# TOP_PBIST_TOP_PBIST register map
Vendor: Texas Instruments
Peripheral module from a debugger description file (folder AM263).
Registers are 32-bit, read-write, reset 0x0 unless marked. A register's access mark holds for its fields unless they carry their own. Offsets are as the file gives them; lines under a group give offsets from that group; [hi:lo] are bit positions; {n}, {i} and the like mark numbered series; 'fields as' and 'values as' point back to an identical list; <NAME> marks a mode.

## TOP_PBIST_TOP_PBIST
0x100 TOP_PBIST_PBIST_A0 16-bit
  [15:0] PBIST_CI2 — TI Internal Register.Reserved for HW RnD
0x104 TOP_PBIST_PBIST_A1 16-bit
  [15:0] PBIST_CI3 — TI Internal Register.Reserved for HW RnD
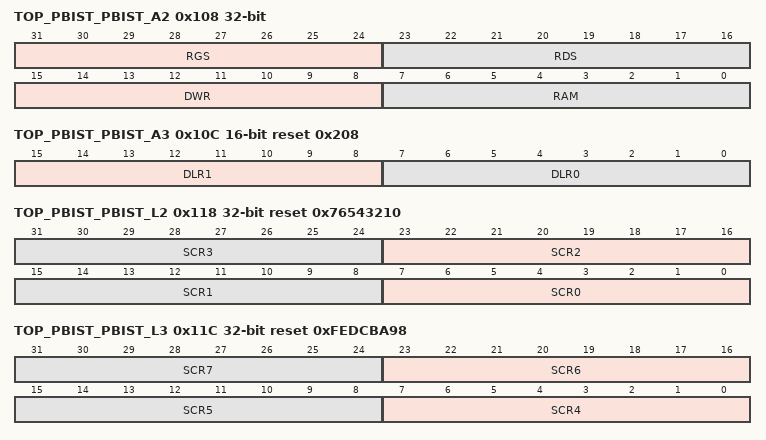
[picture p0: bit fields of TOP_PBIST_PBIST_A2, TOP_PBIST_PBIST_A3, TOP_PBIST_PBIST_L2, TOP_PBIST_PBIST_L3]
0x108 TOP_PBIST_PBIST_A2
  [31:24] RGS — TI Internal Register.Reserved for HW RnD These registers do not have a default value after reset.
  [23:16] RDS — TI Internal Register.Reserved for HW RnD These registers do not have a default value after reset.
  [15:8] DWR — TI Internal Register.Reserved for HW RnD These registers do not have a default value after reset.
  [7:0] RAM — TI Internal Register.Reserved for HW RnD These registers do not have a default value after reset.
0x10C TOP_PBIST_PBIST_A3 16-bit reset 0x208
  [15:8] DLR1 — Datalogger Register[8] : Reserevd[9] : Default Testing Mode. When in this mode, ROM-based testing is kicked off. If the intention is to perform go/no-go testing via config, write to both this bit and bit [2] ofthe Datalogger Register simultaneously[15:10] : Reserevd
  [7:0] DLR0 — Datalogger Register[1:0] : Reserved[2] : ROM-based testing mode. Setting this bit to 1 enables the PBIST controller to execute test algorithms that arestored in the PBIST ROM[3] : Do not change this bit from its default value of 1[4] : Config access mode. Setting this bit allows the host processor to configure the PBIST controller registers[7:5] : Reserved
0x110 TOP_PBIST_PBIST_L0 8-bit
  [3:0] PBIST_CMS — TI Internal Register.Reserved for HW RnD These registers do not have a default value after reset.
0x114 TOP_PBIST_PBIST_L1 8-bit
  [4:0] PBIST_PC — TI Internal Register.Reserved for HW RnD
0x118 TOP_PBIST_PBIST_L2 reset 0x76543210
  [8n+7:8n] SCR{n} (n=0..3) — TI Internal Register.Reserved for HW RnD
0x11C TOP_PBIST_PBIST_L3 reset 0xFEDCBA98
  [8n-25:8n-32] SCR{n} (n=4..7) — TI Internal Register.Reserved for HW RnD
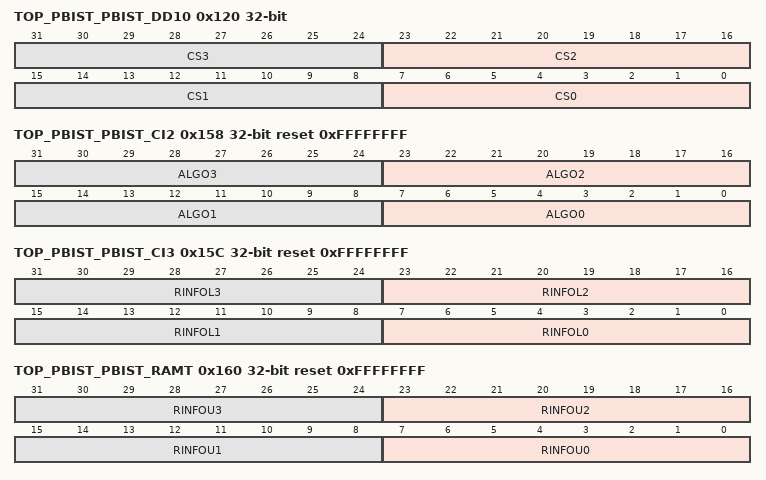
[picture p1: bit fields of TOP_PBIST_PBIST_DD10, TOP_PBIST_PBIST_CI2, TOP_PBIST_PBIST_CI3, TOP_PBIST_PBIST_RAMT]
0x120 TOP_PBIST_PBIST_DD10
  [8n+7:8n] CS{n} (n=0..3) — TI Internal Register.Reserved for HW RnD
0x124 TOP_PBIST_PBIST_DE10 8-bit reset 0x48
  [7:0] PBIST_FDLY — TI Internal Register.Reserved for HW RnD
0x130 TOP_PBIST_PBIST_CA0 size not given
  [0] PBIST_PACT — Pbist Active/ROM Clock Enable Register[0]: This bit must be set to turn on internal PBIST clocks. Setting this bit asserts an internal signal that is usedas the clock gate enable. As long as this bit is 0, any access to PBIST will not go through, and PBIST willremain in an almost zero-power mode.Value 0 = Disable internal PBIST clocksValue 1 = Enable internal PBIST clocks
0x134 TOP_PBIST_PBIST_CA1 8-bit reset 0x1
  [4:0] PBIST_ID — PBIST ID.This is a unique ID assigned to each PBIST controller in a device with multiple PBIST controllers. The value of this register does not affect the functionality of the CPU interface.
0x138 TOP_PBIST_PBIST_CA2 size not given ro
  [0] PBIST_FSFR0 — Fail Status Fail Register- Port 0 This register indicates if a failure occurred during a memory self-test.Value 0 = No failure occurredValue 1 = Indicates a failure
0x13C TOP_PBIST_PBIST_CA3 size not given ro
  [0] PBIST_FSFR1 — Fail Status Fail Register- Port 1 This register indicates if a failure occurred during a memory self-test.Value 0 = No failure occurredValue 1 = Indicates a failure
0x140 TOP_PBIST_PBIST_CL0 8-bit ro
  [3:0] PBIST_FSRCR0 — Fail Status Count - Port 0 These registers keep count of the number of failures observed during the memory self-test. The PBISTcontroller stops executing the memory self-test whenever a failure occurs in any memory instance for anyof the test algorithms. The value in gets incremented by one whenever a failure occurs
0x144 TOP_PBIST_PBIST_CL1 8-bit ro
  [3:0] PBIST_FSRCR1 — Fail Status Count - Port 1These registers keep count of the number of failures observed during the memory self-test. The PBISTcontroller stops executing the memory self-test whenever a failure occurs in any memory instance for anyof the test algorithms. The value in gets incremented by one whenever a failure occurs
0x148 TOP_PBIST_PBIST_CL2 16-bit ro
  [15:0] PBIST_FSRA1 — TI Internal Register.Reserved for HW RnD
0x14C TOP_PBIST_PBIST_CL3 ro reset 0xAAAAAAAA
  [31:0] PBIST_FSRDL0 — TI Internal Register.Reserved for HW RnD
0x150 TOP_PBIST_PBIST_CI0 ro reset 0xAAAAAAAA
  [31:0] PBIST_FSRDL1 — TI Internal Register.Reserved for HW RnD
0x154 TOP_PBIST_PBIST_CI1 8-bit reset 0x3
  [1:0] PBIST_ROM — Rom Mask .This two-bit register sets appropriate ROM access modes for the PBIST controller.Value 0h = No information is used from ROMValue 1h = Only RAM Group information from ROMVaule 2h = Only Algorithm information from ROMValue 3h = Both Algorithm and RAM information from ROM. This option should be selected for application self-test.
0x158 TOP_PBIST_PBIST_CI2 reset 0xFFFFFFFF
  [8n+7:8n] ALGO{n} (n=0..3) — This register is used to indicate the algorithm(s) to be used for the memory self-test routine. Each bit corresponds to a specific algorithm.Writing a value 1 to the particular bit, enables the corresponding algorithm.Writing a value 0 to the particular bit, disables the corresponding algorithm.
0x15C TOP_PBIST_PBIST_CI3 reset 0xFFFFFFFF
  [8n+7:8n] RINFOL{n} (n=0..3) — This register is to select memory groups to run the algorithms selected in the PBIST_ALGO register. For an algorithmto be executed on a particular memory group, the corresponding bit in this register must be set to 1. The default value of this register is all 1s, which means all the memory groups are selected. Writing a value 0 to the particular bit, disables the corresponding memory group.
0x160 TOP_PBIST_PBIST_RAMT reset 0xFFFFFFFF
  [8n+7:8n] RINFOU{n} (n=0..3) — This register is to select memory groups to run the algorithms selected in the PBIST_ALGO register. For an algorithmto be executed on a particular memory group, the corresponding bit in this register must be set to 1. The default value of this register is all 1s, which means all the memory groups are selected. Writing a value 0 to the particular bit, disables the corresponding memory group.
